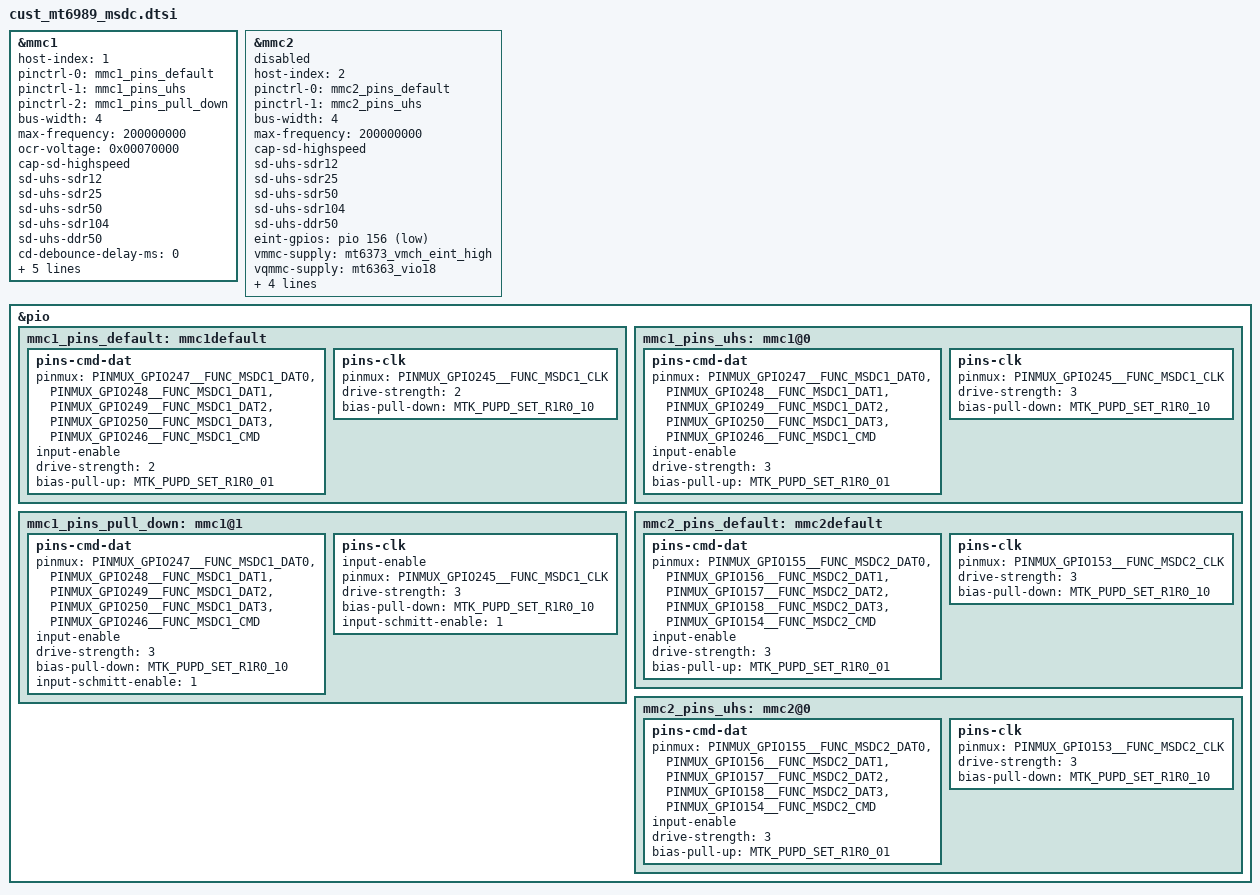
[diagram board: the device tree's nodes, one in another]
// SPDX-License-Identifier: GPL-2.0
/*
 * Copyright (c) 2022 MediaTek Inc.
 */
/********************************************
 * MT6989 MSDC DTSI File
 ********************************************/
#include <dt-bindings/gpio/gpio.h>


&mmc1 {
	host-index = <1>;
	status = "okay";
	pinctrl-names = "default", "state_uhs", "pull_down";
	pinctrl-0 = <&mmc1_pins_default>;
	pinctrl-1 = <&mmc1_pins_uhs>;
	pinctrl-2 = <&mmc1_pins_pull_down>;
	bus-width = <4>;
	max-frequency = <200000000>;
	ocr-voltage = <0x00070000>;
	cap-sd-highspeed;
	sd-uhs-sdr12;
	sd-uhs-sdr25;
	sd-uhs-sdr50;
	sd-uhs-sdr104;
	sd-uhs-ddr50;
	cd-debounce-delay-ms = <0>;
	cd-gpios = <&pio 11 GPIO_ACTIVE_LOW>;
	vmmc-supply = <&mt6373_vmch_eint_high>;
	vqmmc-supply = <&mt6373_vmc>;
	no-mmc;
	no-sdio;
};

&mmc2 {
	host-index = <2>;
	status = "disabled";
	pinctrl-names = "default", "state_uhs";
	pinctrl-0 = <&mmc2_pins_default>;
	pinctrl-1 = <&mmc2_pins_uhs>;
	bus-width = <4>;
	max-frequency = <200000000>;
	cap-sd-highspeed;
	sd-uhs-sdr12;
	sd-uhs-sdr25;
	sd-uhs-sdr50;
	sd-uhs-sdr104;
	sd-uhs-ddr50;
	eint-gpios = <&pio 156 GPIO_ACTIVE_LOW>;
	vmmc-supply = <&mt6373_vmch_eint_high>;
	vqmmc-supply = <&mt6363_vio18>;
	no-mmc;
	no-sd;
	cap-sdio-irq;
	non-removable;
};

&pio {
	mmc1_pins_default: mmc1default {
		pins-cmd-dat {
			pinmux = <PINMUX_GPIO247__FUNC_MSDC1_DAT0>,
				<PINMUX_GPIO248__FUNC_MSDC1_DAT1>,
				<PINMUX_GPIO249__FUNC_MSDC1_DAT2>,
				<PINMUX_GPIO250__FUNC_MSDC1_DAT3>,
				<PINMUX_GPIO246__FUNC_MSDC1_CMD>;
			input-enable;
			drive-strength = <2>;
			bias-pull-up = <MTK_PUPD_SET_R1R0_01>;
		};

		pins-clk {
			pinmux = <PINMUX_GPIO245__FUNC_MSDC1_CLK>;
			drive-strength = <2>;
			bias-pull-down = <MTK_PUPD_SET_R1R0_10>;
		};
	};
	mmc1_pins_uhs: mmc1@0{
		pins-cmd-dat {
			pinmux = <PINMUX_GPIO247__FUNC_MSDC1_DAT0>,
				<PINMUX_GPIO248__FUNC_MSDC1_DAT1>,
				<PINMUX_GPIO249__FUNC_MSDC1_DAT2>,
				<PINMUX_GPIO250__FUNC_MSDC1_DAT3>,
				<PINMUX_GPIO246__FUNC_MSDC1_CMD>;
			input-enable;
			drive-strength = <3>;
			bias-pull-up = <MTK_PUPD_SET_R1R0_01>;
		};

		pins-clk {
			pinmux = <PINMUX_GPIO245__FUNC_MSDC1_CLK>;
			drive-strength = <3>;
			bias-pull-down = <MTK_PUPD_SET_R1R0_10>;
		};
	};
	mmc1_pins_pull_down: mmc1@1{
		pins-cmd-dat {
			pinmux = <PINMUX_GPIO247__FUNC_MSDC1_DAT0>,
				<PINMUX_GPIO248__FUNC_MSDC1_DAT1>,
				<PINMUX_GPIO249__FUNC_MSDC1_DAT2>,
				<PINMUX_GPIO250__FUNC_MSDC1_DAT3>,
				<PINMUX_GPIO246__FUNC_MSDC1_CMD>;
			input-enable;
			drive-strength = <3>;
			bias-pull-down = <MTK_PUPD_SET_R1R0_10>;
			input-schmitt-enable = <1>;
		};
 

		pins-clk {
			input-enable;
			pinmux = <PINMUX_GPIO245__FUNC_MSDC1_CLK>;
			drive-strength = <3>;
			bias-pull-down = <MTK_PUPD_SET_R1R0_10>;
			input-schmitt-enable = <1>;
		};
	};
	mmc2_pins_default: mmc2default {
		pins-cmd-dat {
			pinmux = <PINMUX_GPIO155__FUNC_MSDC2_DAT0>,
				<PINMUX_GPIO156__FUNC_MSDC2_DAT1>,
				<PINMUX_GPIO157__FUNC_MSDC2_DAT2>,
				<PINMUX_GPIO158__FUNC_MSDC2_DAT3>,
				<PINMUX_GPIO154__FUNC_MSDC2_CMD>;
			input-enable;
			drive-strength = <3>;
			bias-pull-up = <MTK_PUPD_SET_R1R0_01>;
		};
		pins-clk {
			pinmux = <PINMUX_GPIO153__FUNC_MSDC2_CLK>;
			drive-strength = <3>;
			bias-pull-down = <MTK_PUPD_SET_R1R0_10>;
		};
	};
	mmc2_pins_uhs: mmc2@0{
		pins-cmd-dat {
			pinmux = <PINMUX_GPIO155__FUNC_MSDC2_DAT0>,
				<PINMUX_GPIO156__FUNC_MSDC2_DAT1>,
				<PINMUX_GPIO157__FUNC_MSDC2_DAT2>,
				<PINMUX_GPIO158__FUNC_MSDC2_DAT3>,
				<PINMUX_GPIO154__FUNC_MSDC2_CMD>;
			input-enable;
			drive-strength = <3>;
			bias-pull-up = <MTK_PUPD_SET_R1R0_01>;
		};
		pins-clk {
			pinmux = <PINMUX_GPIO153__FUNC_MSDC2_CLK>;
			drive-strength = <3>;
			bias-pull-down = <MTK_PUPD_SET_R1R0_10>;
		};
	};
};


